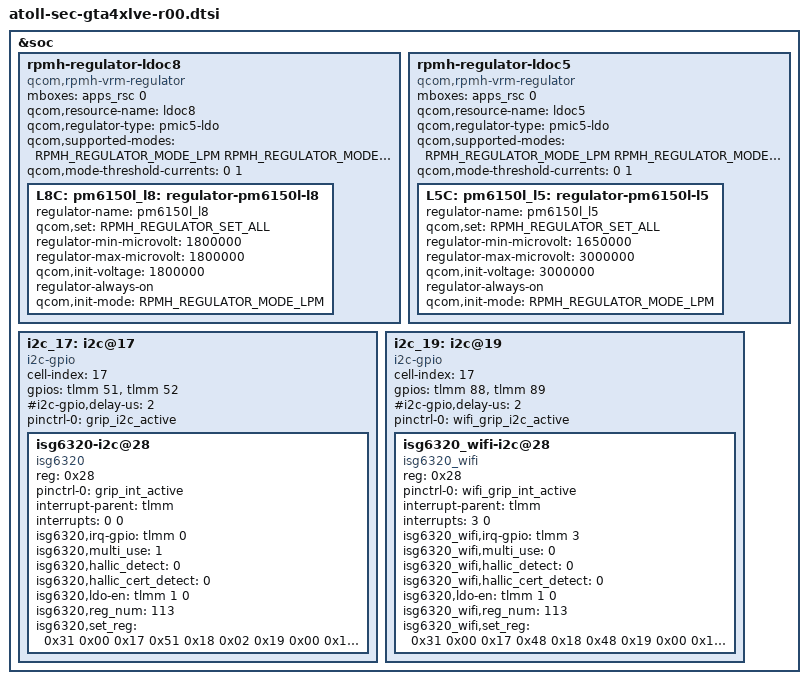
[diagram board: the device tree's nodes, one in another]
/* Copyright (c) 2020, The Linux Foundation. All rights reserved.
 *
 * This program is free software; you can redistribute it and/or modify
 * it under the terms of the GNU General Public License version 2 and
 * only version 2 as published by the Free Software Foundation.
 *
 * This program is distributed in the hope that it will be useful,
 * but WITHOUT ANY WARRANTY; without even the implied warranty of
 * MERCHANTABILITY or FITNESS FOR A PARTICULAR PURPOSE.  See the
 * GNU General Public License for more details.
 */

#include "atoll-sec-gta4xlve-common.dtsi"
#include "atoll-sec-gta4xlve-pinctrl-r00.dtsi"
#include "atoll-sec-gta4xlve-pm-common.dtsi"
#include "atoll-sec-gta4xlve-display-r00.dtsi"
#include "atoll-sec-gta4xlve-input-common.dtsi"
#include <dt-bindings/regulator/qcom,rpmh-regulator.h>
#include "../drivers/atoll-sec-gta4xlve-audio-common.dtsi"
#include "../drivers/atoll-sec-gta4xlve-usb-r00.dtsi"
#include "../drivers/atoll-sec-gta4xlve-battery-common.dtsi"
#include "atoll-sec-gta4xlve-camera-sensor-common.dtsi" 
#include "../drivers/atoll-sec-gta4xlve-abc-r00.dtsi"


&soc {
	//Sensor Vdd
	rpmh-regulator-ldoc8 {
		compatible = "qcom,rpmh-vrm-regulator";
		mboxes = <&apps_rsc 0>;
		qcom,resource-name = "ldoc8";
		qcom,regulator-type = "pmic5-ldo";
		qcom,supported-modes =
			<RPMH_REGULATOR_MODE_LPM
			RPMH_REGULATOR_MODE_HPM>;
		qcom,mode-threshold-currents = <0 1>;
		L8C:
		pm6150l_l8: regulator-pm6150l-l8 {
			regulator-name = "pm6150l_l8";
			qcom,set = <RPMH_REGULATOR_SET_ALL>;
			regulator-min-microvolt = <1800000>;
			regulator-max-microvolt = <1800000>;
			qcom,init-voltage = <1800000>;
			regulator-always-on;
			qcom,init-mode =
				<RPMH_REGULATOR_MODE_LPM>;
		};
	};

	rpmh-regulator-ldoc5 {
		compatible = "qcom,rpmh-vrm-regulator";
		mboxes = <&apps_rsc 0>;
		qcom,resource-name = "ldoc5";
		qcom,regulator-type = "pmic5-ldo";
		qcom,supported-modes =
				<RPMH_REGULATOR_MODE_LPM
				RPMH_REGULATOR_MODE_HPM>;
		qcom,mode-threshold-currents = <0 1>;
		L5C: pm6150l_l5: regulator-pm6150l-l5 {
			regulator-name = "pm6150l_l5";
			qcom,set = <RPMH_REGULATOR_SET_ALL>;
			regulator-min-microvolt = <1650000>;
			regulator-max-microvolt = <3000000>;
			qcom,init-voltage = <3000000>;
			regulator-always-on;
			qcom,init-mode = <RPMH_REGULATOR_MODE_LPM>;
		};
	};

	i2c_17: i2c@17 { /* SW I2C */
		status = "ok";

		cell-index = <17>;
		compatible = "i2c-gpio";
		gpios = <&tlmm 51 0 /* sda */
			 &tlmm 52 0 /* scl */
		>;
		#i2c-gpio,delay-us = <2>;
		#address-cells = <1>;
		#size-cells = <0>;
		pinctrl-names = "default";
		pinctrl-0 = <&grip_i2c_active>;

		isg6320-i2c@28 {
			compatible = "isg6320";
			reg = <0x28>;
			status = "okay";
			pinctrl-names = "default";
			pinctrl-0 = <&grip_int_active>;
			interrupt-parent = <&tlmm>;
			interrupts = <0 0>;

			isg6320,irq-gpio = <&tlmm 0 0>;

			isg6320,multi_use = <1>;
			isg6320,hallic_detect = <0>;
			isg6320,hallic_cert_detect = <0>;
			isg6320,ldo-en = <&tlmm 1 0>;
			isg6320,reg_num = <113>;
			isg6320,set_reg = /bits/ 8 <
				0x31 0x00
				0x17 0x51
				0x18 0x02
				0x19 0x00
				0x1A 0x29
				0x1B 0x4A
				0x1C 0x4F
				0x1D 0x21
				0x1E 0x27
				0x1F 0x0D
				0x20 0x21
				0x21 0x21
				0x22 0x36
				0x23 0x4A
				0x24 0x0D
				0x25 0x36
				0x26 0x4A
				0x27 0x0D
				0x28 0x21
				0x2B 0x2F
				0x2F 0x77
				0x38 0x31
				0x60 0x05
				0x61 0x07
				0x62 0x78
				0x91 0x78
				0x65 0x32
				0x67 0x46
				0x68 0x2A
				0x69 0x40
				0x6A 0x00
				0x6C 0x80
				0x6D 0x95
				0x6E 0x44
				0x6F 0x08
				0x70 0x60
				0x71 0xC0
				0x72 0x60
				0x73 0x00
				0x74 0xED
				0x75 0xF6
				0x76 0xED
				0x77 0xF0
				0x78 0x8A
				0x79 0xF0
				0x7C 0x12
				0x7D 0x19
				0x7E 0x6D
				0x80 0x37
				0x81 0x4E
				0x89 0x01
				0x8A 0x69
				0x8B 0x7D
				0x8C 0x7D
				0x94 0x05
				0x95 0x08
				0x96 0x78
				0xC5 0x78
				0x99 0x32
				0x9B 0x46
				0x9C 0x2A
				0x9D 0x40
				0x9E 0x00
				0xA0 0x80
				0xA1 0x95
				0xA2 0x44
				0xA3 0x08
				0xA4 0x60
				0xA5 0xD0
				0xA6 0x60
				0xA7 0x00
				0xA8 0xED
				0xA9 0xF6
				0xAA 0xED
				0xAB 0xF0
				0xAC 0x8A
				0xAD 0xF0
				0xB0 0x12
				0xB1 0x19
				0xB2 0x6D
				0xB4 0x37
				0xB5 0x4E
				0xBD 0x01
				0xBE 0x69
				0xBF 0x7D
				0xC0 0x7D
				0x51 0x0A
				0x52 0x10
				0x55 0x10
				0x56 0x20
				0x59 0x18
				0x5A 0x05
				0xD1 0x08
				0xD2 0x10
				0xD5 0x10
				0xD6 0x20
				0xD9 0x10
				0xDA 0x05
				0x37 0x33
				0x90 0x13
				0xC4 0x13
				0x05 0xB8
				0x06 0x80
				0x07 0x0D
				0x08 0x01
				0x09 0x4C
				0x0F 0xAB
				0x11 0x06
				0x12 0x08
				0x14 0x33
				0x15 0x13
				0x16 0x13
				0x2C 0x03
				>;
		};
	};

	i2c_19: i2c@19 { /* SW I2C */
		status = "ok";

		cell-index = <17>;
		compatible = "i2c-gpio";
		gpios = <&tlmm 88 0 /* sda */
			 &tlmm 89 0 /* scl */
		>;
		#i2c-gpio,delay-us = <2>;
		#address-cells = <1>;
		#size-cells = <0>;
		pinctrl-names = "default";
		pinctrl-0 = <&wifi_grip_i2c_active>;

		isg6320_wifi-i2c@28 {
			compatible = "isg6320_wifi";
			reg = <0x28>;
			status = "okay";
			pinctrl-names = "default";
			pinctrl-0 = <&wifi_grip_int_active>;
			interrupt-parent = <&tlmm>;
			interrupts = <3 0>;

			isg6320_wifi,irq-gpio = <&tlmm 3 0>;

			isg6320_wifi,multi_use = <0>;
			isg6320_wifi,hallic_detect = <0>;
			isg6320_wifi,hallic_cert_detect = <0>;
			isg6320,ldo-en = <&tlmm 1 0>;
			isg6320_wifi,reg_num = <113>;
			isg6320_wifi,set_reg = /bits/ 8 <
				0x31 0x00
				0x17 0x48
				0x18 0x48
				0x19 0x00
				0x1A 0x24
				0x1B 0x41
				0x1C 0x46
				0x1D 0x1C
				0x1E 0x22
				0x1F 0x0A
				0x20 0x1C
				0x21 0x1C
				0x22 0x2F
				0x23 0x41
				0x24 0x0A
				0x25 0x2F
				0x26 0x41
				0x27 0x0A
				0x28 0x1C
				0x2B 0x2C
				0x2F 0x71
				0x38 0x31
				0x60 0x05
				0x61 0xCD
				0x62 0x48
				0x91 0x48
				0x65 0x22
				0x67 0x46
				0x68 0x2A
				0x69 0x40
				0x6A 0x00
				0x6C 0x80
				0x6D 0x31
				0x6E 0x44
				0x6F 0x08
				0x70 0x60
				0x71 0xA0
				0x72 0x40
				0x73 0x00
				0x74 0xED
				0x75 0x40
				0x76 0xED
				0x77 0x80
				0x78 0xA0
				0x79 0xA0
				0x7C 0x12
				0x7D 0x15
				0x7E 0x6D
				0x80 0x37
				0x81 0x4E
				0x89 0x01
				0x8A 0x69
				0x8B 0x7D
				0x8C 0x7D
				0x94 0x05
				0x95 0xCD
				0x96 0x48
				0xC5 0x48
				0x99 0x22
				0x9B 0x46
				0x9C 0x2A
				0x9D 0x40
				0x9E 0x00
				0xA0 0x80
				0xA1 0x31
				0xA2 0x44
				0xA3 0x08
				0xA4 0x60
				0xA5 0xA0
				0xA6 0x40
				0xA7 0x00
				0xA8 0xED
				0xA9 0x40
				0xAA 0xED
				0xAB 0x80
				0xAC 0xA0
				0xAD 0xA0
				0xB0 0x12
				0xB1 0x15
				0xB2 0x6D
				0xB4 0x37
				0xB5 0x4E
				0xBD 0x01
				0xBE 0x69
				0xBF 0x7D
				0xC0 0x7D
				0x51 0x08
				0x52 0x10
				0x55 0x10
				0x56 0x20
				0x59 0x10
				0x5A 0x05
				0xD1 0x08
				0xD2 0x10
				0xD5 0x10
				0xD6 0x20
				0xD9 0x10
				0xDA 0x05
				0x37 0x33
				0x90 0x13
				0xC4 0x13
				0x05 0xB8
				0x06 0x80
				0x07 0x0D
				0x08 0x01
				0x09 0x4C
				0x0F 0xAB
				0x11 0x06
				0x12 0x08
				0x14 0x33
				0x15 0x13
				0x16 0x13
				0x2C 0x03
				>;
		};
	};
};
